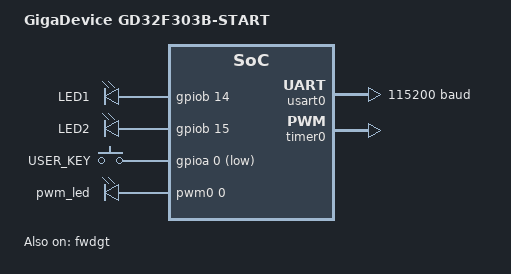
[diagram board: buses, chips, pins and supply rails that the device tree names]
/*
 * Copyright (c) 2026, GigaDevice Semiconductor Inc.
 * SPDX-License-Identifier: Apache-2.0
 */
/dts-v1/;

#include <gd/gd32f30x/gd32f303.dtsi>
#include "gd32f303b_start-pinctrl.dtsi"
#include <zephyr/dt-bindings/input/input-event-codes.h>

/ {
	model = "GigaDevice GD32F303B-START";
	compatible = "gd,gd32f303b-start";

	chosen {
		zephyr,sram = &sram0;
		zephyr,flash = &flash0;
		zephyr,console = &usart0;
		zephyr,shell-uart = &usart0;
		zephyr,flash-controller = &fmc;
	};

	leds {
		compatible = "gpio-leds";

		led1: led1 {
			gpios = <&gpiob 14 GPIO_ACTIVE_HIGH>;
			label = "LED1";
		};

		led2: led2 {
			gpios = <&gpiob 15 GPIO_ACTIVE_HIGH>;
			label = "LED2";
		};
	};

	gpio_keys {
		compatible = "gpio-keys";

		user_key: user_key {
			label = "USER_KEY";
			gpios = <&gpioa 0 GPIO_ACTIVE_LOW>;
			zephyr,code = <INPUT_KEY_0>;
		};
	};

	pwmleds {
		compatible = "pwm-leds";

		/* NOTE: bridge TIMER0_CH0 (PA8) and LED1 (PB14) */
		pwm_led: pwm_led {
			pwms = <&pwm0 0 PWM_MSEC(20) PWM_POLARITY_NORMAL>;
		};
	};

	aliases {
		led0 = &led1;
		led1 = &led2;
		sw0 = &user_key;
		pwm-led0 = &pwm_led;
		watchdog0 = &fwdgt;
	};
};

/* GD32F303CBT6: 128KB Flash */
&flash0 {
	reg = <0x08000000 DT_SIZE_K(128)>;
};

&gpioa {
	status = "okay";
};

&gpiob {
	status = "okay";
};

&usart0 {
	status = "okay";
	current-speed = <115200>;
	pinctrl-0 = <&usart0_default>;
	pinctrl-names = "default";
};

&timer0 {
	status = "okay";
	prescaler = <256>;

	pwm0: pwm {
		status = "okay";
		pinctrl-0 = <&pwm0_default>;
		pinctrl-names = "default";
	};
};

&fwdgt {
	status = "okay";
};
